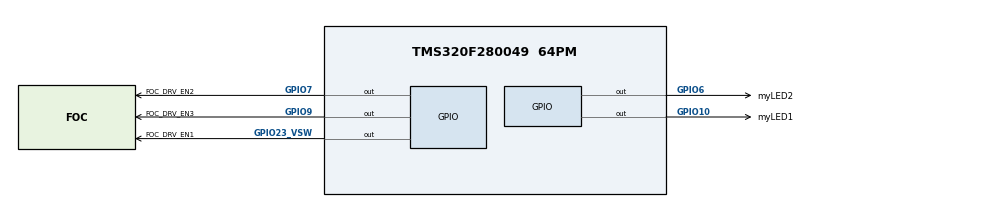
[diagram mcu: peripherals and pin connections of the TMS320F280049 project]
/**
 * These arguments were used when this file was generated. They will be automatically applied on subsequent loads
 * via the GUI or CLI. Run CLI with '--help' for additional information on how to override these arguments.
 * @cliArgs --device "F28004x" --part "F28004x_64PM" --package "F28004x_64PM" --context "system" --product "C2000WARE@6.00.00.00"
 * @v2CliArgs --device "TMS320F280049" --package "64PM" --context "system" --product "C2000WARE@6.00.00.00"
 * @versions {"tool":"1.25.0+4268"}
 */

/**
 * Import the modules used in this configuration.
 */
const led       = scripting.addModule("/driverlib/board_components/led", {}, false);
const led1      = led.addInstance();
const led2      = led.addInstance();
const cputimer  = scripting.addModule("/driverlib/cputimer.js", {}, false);
const cputimer1 = cputimer.addInstance();
const gpio      = scripting.addModule("/driverlib/gpio.js", {}, false);
const gpio3     = gpio.addInstance();
const gpio4     = gpio.addInstance();
const gpio5     = gpio.addInstance();
const FREERTOS  = scripting.addModule("/kernel/freertos_tool/FREERTOS", {}, false);
const FREERTOS1 = FREERTOS.addInstance();

/**
 * Write custom configuration values to the imported modules.
 */
led1.$name                  = "myLED1";
led1.gpio.writeInitialValue = true;
led1.gpio.initialValue      = 1;
led1.gpio.gpioPin.$assign   = "GPIO10";

led2.$name                  = "myLED2";
led2.gpio.writeInitialValue = true;
led2.gpio.initialValue      = 1;
led2.gpio.gpioPin.$assign   = "GPIO6";

const divider1       = system.clockTree["CLBCLKDIV"];
divider1.divideValue = 4;

const divider2       = system.clockTree["LOSPCP"];
divider2.divideValue = 1;

cputimer1.$name                     = "timer1";
cputimer1.cputimerBase              = "CPUTIMER1_BASE";
cputimer1.enableInterrupt           = true;
cputimer1.registerInterrupts        = true;
cputimer1.startTimer                = true;
cputimer1.timerPeriod               = 10000000;
cputimer1.timerInt.interruptHandler = "timer1_ISR";
cputimer1.timerInt.enableInterrupt  = true;

gpio3.$name           = "FOC_DRV_EN1";
gpio3.direction       = "GPIO_DIR_MODE_OUT";
gpio3.gpioPin.$assign = "GPIO23_VSW";

gpio4.$name           = "FOC_DRV_EN2";
gpio4.direction       = "GPIO_DIR_MODE_OUT";
gpio4.gpioPin.$assign = "GPIO7";

gpio5.$name           = "FOC_DRV_EN3";
gpio5.direction       = "GPIO_DIR_MODE_OUT";
gpio5.gpioPin.$assign = "GPIO9";

FREERTOS1.$name                   = "myFREERTOS0";
FREERTOS1.MINIMAL_STACK_SIZE      = 256;
FREERTOS1.USE_MUTEXES             = true;
FREERTOS1.USE_RECURSIVE_MUTEXES   = true;
FREERTOS1.USE_COUNTING_SEMAPHORES = true;
FREERTOS1.vTaskSuspend            = false;
FREERTOS1.tasks.create(2);
FREERTOS1.tasks[0].$name          = "myTask0";
FREERTOS1.tasks[0].taskPointer    = "myTask0_func";
FREERTOS1.tasks[1].$name          = "FOC_Task";
FREERTOS1.tasks[1].taskPointer    = "FOC_Task_Func";
